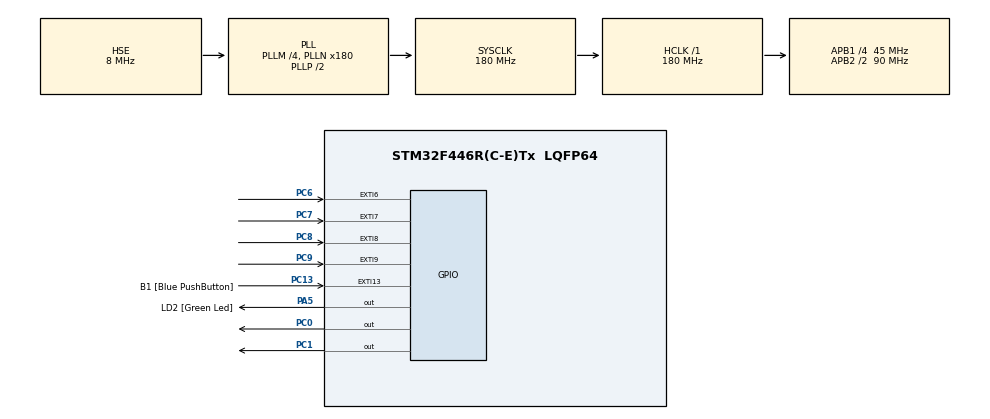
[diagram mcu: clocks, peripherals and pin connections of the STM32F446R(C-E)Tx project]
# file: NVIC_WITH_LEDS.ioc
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Mcu.Family=STM32F4
Mcu.Name=STM32F446R(C-E)Tx
Mcu.Package=LQFP64
NVIC.EXTI15_10_IRQn=true\:1\:0\:true\:false\:true\:true\:true
NVIC.EXTI9_5_IRQn=true\:1\:0\:true\:false\:true\:true\:true
NVIC.PriorityGroup=NVIC_PRIORITYGROUP_4
PA13.GPIO_Label=TMS
PA13.Mode=Serial_Wire
PA13.Signal=SYS_JTMS-SWDIO
PA14.GPIO_Label=TCK
PA14.Mode=Serial_Wire
PA14.Signal=SYS_JTCK-SWCLK
PA2.GPIO_Label=USART_TX
PA2.Signal=USART2_TX
PA3.GPIO_Label=USART_RX
PA3.Signal=USART2_RX
PA5.GPIO_Label=LD2 [Green Led]
PA5.Signal=GPIO_Output
PB3.GPIO_Label=SWO
PB3.Signal=SYS_JTDO-SWO
PC0.Signal=GPIO_Output
PC1.Signal=GPIO_Output
PC13.GPIO_Label=B1 [Blue PushButton]
PC13.GPIO_ModeDefaultEXTI=GPIO_MODE_IT_FALLING
PC13.Signal=GPXTI13
PC14-OSC32_IN.Signal=RCC_OSC32_IN
PC15-OSC32_OUT.Signal=RCC_OSC32_OUT
PC6.Signal=GPXTI6
PC7.Signal=GPXTI7
PC8.Signal=GPXTI8
PC9.Signal=GPXTI9
PH0-OSC_IN.Mode=HSE-External-Clock-Source
PH0-OSC_IN.Signal=RCC_OSC_IN
PH1-OSC_OUT.Mode=HSE-External-Clock-Source
PH1-OSC_OUT.Signal=RCC_OSC_OUT
ProjectManager.HeapSize=0x200
ProjectManager.StackSize=0x400
ProjectManager.TargetToolchain=STM32CubeIDE
RCC.AHBFreq_Value=180000000
RCC.APB1CLKDivider=RCC_HCLK_DIV4
RCC.APB1Freq_Value=45000000
RCC.APB1TimFreq_Value=90000000
RCC.APB2CLKDivider=RCC_HCLK_DIV2
RCC.APB2Freq_Value=90000000
RCC.APB2TimFreq_Value=180000000
RCC.CortexFreq_Value=180000000
RCC.FLatency-AdvancedSettings=FLASH_LATENCY_5
RCC.HCLKFreq_Value=180000000
RCC.HSE_VALUE=8000000
RCC.HSI_VALUE=16000000
RCC.LSE_VALUE=32768
RCC.PLLM=4
RCC.PLLN=180
RCC.PLLSourceVirtual=RCC_PLLSOURCE_HSE
RCC.SYSCLKFreq_VALUE=180000000
RCC.SYSCLKSource=RCC_SYSCLKSOURCE_PLLCLK
RCC.USBFreq_Value=180000000
RCC.VCOOutputFreq_Value=360000000
board=NUCLEO-F446RE

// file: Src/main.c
/* USER CODE BEGIN Header */
/**
  ******************************************************************************
  * @file           : main.c
  * @brief          : Main program body
  ******************************************************************************
  * @attention
  *
  * <h2><center>&copy; Copyright (c) 2019 STMicroelectronics.
  * All rights reserved.</center></h2>
  *
  * This software component is licensed by ST under BSD 3-Clause license,
  * the "License"; You may not use this file except in compliance with the
  * License. You may obtain a copy of the License at:
  *                        opensource.org/licenses/BSD-3-Clause
  *
  ******************************************************************************
  */
/* USER CODE END Header */

#include "main.h"
#include "gpio.h"

/* USER CODE BEGIN Includes */
volatile uint32_t start , tick;
/* USER CODE END Includes */

void SystemClock_Config(void);

int main(void)
{

  /* MCU Configuration--------------------------------------------------------*/

  /* Reset of all peripherals, Initializes the Flash interface and the Systick. */
  HAL_Init();

  /* Configure the system clock */
  SystemClock_Config();

  /* Initialize all configured peripherals */
  MX_GPIO_Init();
  /* USER CODE BEGIN 2 */

  tick = 500;
  start = HAL_GetTick();
  /* USER CODE END 2 */

  /* Infinite loop */
  while (1)
  {
     if (HAL_GetTick() - start >= tick){
      start = HAL_GetTick();
      HAL_GPIO_TogglePin(GPIOC, GPIO_PIN_0);
     }

  }
  /* USER CODE END 3 */
}

void SystemClock_Config(void)
{
  RCC_OscInitTypeDef RCC_OscInitStruct = {0};
  RCC_ClkInitTypeDef RCC_ClkInitStruct = {0};

  /** Configure the main internal regulator output voltage
  */
  __HAL_RCC_PWR_CLK_ENABLE();
  __HAL_PWR_VOLTAGESCALING_CONFIG(PWR_REGULATOR_VOLTAGE_SCALE1);
  /** Initializes the CPU, AHB and APB busses clocks
  */
  RCC_OscInitStruct.OscillatorType = RCC_OSCILLATORTYPE_HSE;
  RCC_OscInitStruct.HSEState = RCC_HSE_BYPASS;
  RCC_OscInitStruct.PLL.PLLState = RCC_PLL_ON;
  RCC_OscInitStruct.PLL.PLLSource = RCC_PLLSOURCE_HSE;
  RCC_OscInitStruct.PLL.PLLM = 4;
  RCC_OscInitStruct.PLL.PLLN = 180;
  RCC_OscInitStruct.PLL.PLLP = RCC_PLLP_DIV2;
  RCC_OscInitStruct.PLL.PLLQ = 2;
  RCC_OscInitStruct.PLL.PLLR = 2;
  if (HAL_RCC_OscConfig(&RCC_OscInitStruct) != HAL_OK)
  {
    Error_Handler();
  }
  /** Activate the Over-Drive mode
  */
  if (HAL_PWREx_EnableOverDrive() != HAL_OK)
  {
    Error_Handler();
  }
  /** Initializes the CPU, AHB and APB busses clocks
  */
  RCC_ClkInitStruct.ClockType = RCC_CLOCKTYPE_HCLK|RCC_CLOCKTYPE_SYSCLK
                              |RCC_CLOCKTYPE_PCLK1|RCC_CLOCKTYPE_PCLK2;
  RCC_ClkInitStruct.SYSCLKSource = RCC_SYSCLKSOURCE_PLLCLK;
  RCC_ClkInitStruct.AHBCLKDivider = RCC_SYSCLK_DIV1;
  RCC_ClkInitStruct.APB1CLKDivider = RCC_HCLK_DIV4;
  RCC_ClkInitStruct.APB2CLKDivider = RCC_HCLK_DIV2;

  if (HAL_RCC_ClockConfig(&RCC_ClkInitStruct, FLASH_LATENCY_5) != HAL_OK)
  {
    Error_Handler();
  }
}

void Error_Handler(void)
{
}

/************************ (C) COPYRIGHT STMicroelectronics *****END OF FILE****/
